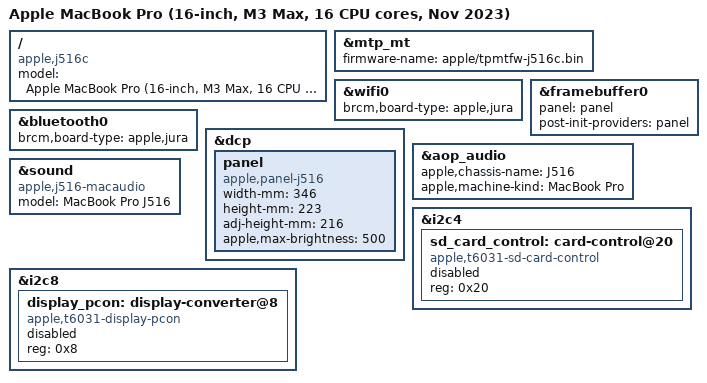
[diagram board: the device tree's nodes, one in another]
// SPDX-License-Identifier: GPL-2.0+ OR MIT
/*
 * MacBook Pro (16-inch, M3 Max, 16 CPU cores, Nov 2023)
 *
 * target-type: J516c
 *
 * Copyright The Asahi Linux Contributors
 */

/dts-v1/;

#include "t6031.dtsi"
#include "t6031-dcp.dtsi"
#include "t603x-j514-j516.dtsi"

/ {
	compatible = "apple,j516c", "apple,t6031", "apple,arm-platform";
	model = "Apple MacBook Pro (16-inch, M3 Max, 16 CPU cores, Nov 2023)";
};

&mtp_mt {
	firmware-name = "apple/tpmtfw-j516c.bin";
};

&wifi0 {
	brcm,board-type = "apple,jura";
};

&bluetooth0 {
	brcm,board-type = "apple,jura";
};

/* The J516S panel: the same chassis. Not yet read from a J516C. */
&dcp {
	panel: panel {
		compatible = "apple,panel-j516", "apple,panel-mini-led", "apple,panel";
		width-mm = <346>;
		height-mm = <223>;
		adj-height-mm = <216>;
		apple,max-brightness = <500>;
	};
};

&framebuffer0 {
	panel = <&panel>;
	post-init-providers = <&panel>;
};

&aop_audio {
	apple,chassis-name = "J516";
	apple,machine-kind = "MacBook Pro";
};

&sound {
	compatible = "apple,j516-macaudio", "apple,j316-macaudio", "apple,macaudio";
	model = "MacBook Pro J516";
};


&i2c4 {
	sd_card_control: card-control@20 {
		compatible = "apple,t6031-sd-card-control", "apple,sd-card-control";
		reg = <0x20>;
		status = "disabled";
	};
};

&i2c8 {
	display_pcon: display-converter@8 {
		compatible = "apple,t6031-display-pcon", "apple,display-pcon";
		reg = <0x8>;
		status = "disabled";
	};
};
